# R7FA6M4AF register map
Vendor: Renesas Electronics Corporation; Series: RA6; File version: 1.30.00
CPU: CM33 r0p4, little endian, MPU, FPU, VTOR, 4 interrupt priority bits, 96 interrupts
Registers are 8-bit, read-write, reset 0x0 unless marked. A register's access mark holds for its fields unless they carry their own. Offsets are from the block's base; [hi:lo] are bit positions; {n}, {i} and the like mark numbered series; 'fields as' and 'values as' point back to an identical list.

## CAN0 — Controller Area Network 0
Base 0x400A8000
Same registers: CAN1 0x400A9000
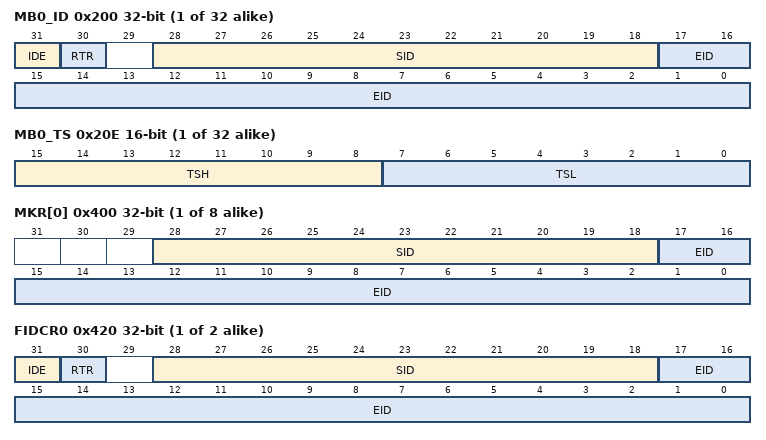
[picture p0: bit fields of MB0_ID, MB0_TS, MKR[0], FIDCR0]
{0x200+0x10*i} MB{i}_ID (i=0..31) 32-bit (reset mask 0x1) — Mailbox ID Register {i}
  [31] IDE — ID Extension
  [30] RTR — Remote Transmission Request
  [28:18] SID — Standard ID of data and remote frames
  [17:0] EID — Extended ID of data and remote frames
{0x204+0x10*i} MB{i}_DL (i=0..31) 16-bit reset not defined — Mailbox Data Length Register {i}
  [3:0] DLC — Data Length Code
{0x206+0x10*i} MB{i}_D0 (i=0..31) reset not defined — Mailbox Data Register {i}
  [7:0] DATA0 — Data Bytes 0
{0x207+0x10*i} MB{i}_D1 (i=0..31) reset not defined — Mailbox Data Register {i}
  [7:0] DATA1 — Data Bytes 1
{0x208+0x10*i} MB{i}_D2 (i=0..31) reset not defined — Mailbox Data Register {i}
  [7:0] DATA2 — Data Bytes 2
{0x209+0x10*i} MB{i}_D3 (i=0..31) reset not defined — Mailbox Data Register {i}
  [7:0] DATA3 — Data Bytes 3
{0x20A+0x10*i} MB{i}_D4 (i=0..31) reset not defined — Mailbox Data Register {i}
  [7:0] DATA4 — Data Bytes 4
{0x20B+0x10*i} MB{i}_D5 (i=0..31) reset not defined — Mailbox Data Register {i}
  [7:0] DATA5 — Data Bytes 5
{0x20C+0x10*i} MB{i}_D6 (i=0..31) reset not defined — Mailbox Data Register {i}
  [7:0] DATA6 — Data Bytes 6
{0x20D+0x10*i} MB{i}_D7 (i=0..31) reset not defined — Mailbox Data Register {i}
  [7:0] DATA7 — Data Bytes 7
{0x20E+0x10*i} MB{i}_TS (i=0..31) 16-bit reset not defined — Mailbox Time Stamp Register {i}
  [15:8] TSH — Time Stamp Higher Byte
  [7:0] TSL — Time Stamp Lower Byte
{0x400+4i} MKR[{i}] (i=0..7) 32-bit reset not defined — Mask Register {i}
  [28:18] SID — Standard ID
  [17:0] EID — Extended ID
{0x420+4i} FIDCR{i} (i=0..1) 32-bit reset not defined — FIFO Received ID Compare Register {i}
  fields as MB0_ID
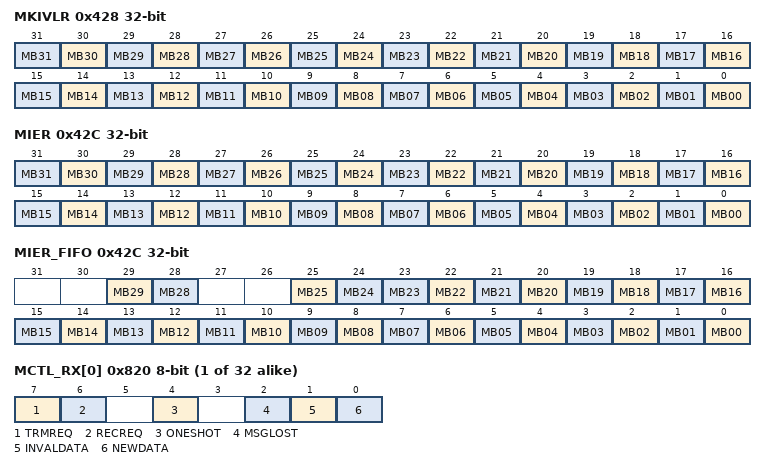
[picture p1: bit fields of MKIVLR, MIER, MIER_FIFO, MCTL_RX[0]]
0x428 MKIVLR 32-bit reset not defined — Mask Invalid Register
  [n] MB{n:02} (n=0..31) — Mask Invalid
0x42C MIER 32-bit reset not defined — Mailbox Interrupt Enable Register
  [n] MB{n:02} (n=0..31) — Interrupt Enable
0x42C MIER_FIFO 32-bit reset not defined (alternate view of MIER) — Mailbox Interrupt Enable Register for FIFO Mailbox Mode
  [29] MB29 — Receive FIFO Interrupt Generation Timing Control
  [28] MB28 — Receive FIFO Interrupt Enable
  [25] MB25 — Transmit FIFO Interrupt Generation Timing Control
  [24] MB24 — Transmit FIFO Interrupt Enable
  [n] MB{n:02} (n=0..23) — Interrupt Enable
{0x820+i} MCTL_RX[{i}] (i=0..31) — Message Control Register for Receive
  [7] TRMREQ — Transmit Mailbox Request
  [6] RECREQ — Receive Mailbox Request
  [4] ONESHOT — One,Shot Enable
  [2] MSGLOST — Message Lost Flag
  [1] INVALDATA ro — Reception,in,Progress Status Flag
  [0] NEWDATA — Reception Complete Flag
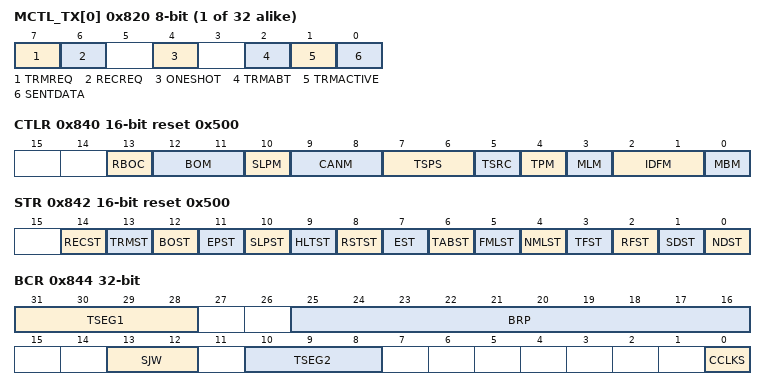
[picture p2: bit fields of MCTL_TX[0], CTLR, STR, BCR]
{0x820+i} MCTL_TX[{i}] (i=0..31) (alternate view of MCTL_RX[{i}]) — Message Control Register for Transmit
  [7] TRMREQ — Transmit Mailbox Request
  [6] RECREQ — Receive Mailbox Request
  [4] ONESHOT — One,Shot Enable
  [2] TRMABT — Transmission Abort Complete Flag
  [1] TRMACTIVE ro — Transmission,in,Progress Status Flag
  [0] SENTDATA — Transmission Complete Flag
0x840 CTLR 16-bit reset 0x500 — Control Register
  [13] RBOC — Forcible Return from Bus,Off
  [12:11] BOM — Bus,Off Recovery Mode
  [10] SLPM — CAN Sleep Mode
  [9:8] CANM — CAN Operating Mode Select
  [7:6] TSPS — Time Stamp Prescaler Select
  [5] TSRC — Time Stamp Counter Reset Command
  [4] TPM — Transmission Priority Mode Select
  [3] MLM — Message Lost Mode Select
  [2:1] IDFM — ID Format Mode Select
  [0] MBM — CAN Mailbox Mode Select
0x842 STR 16-bit ro reset 0x500 — Status Register
  [14] RECST — Receive Status Flag
  [13] TRMST — Transmit Status Flag
  [12] BOST — Bus,Off Status Flag
  [11] EPST — Error,Passive Status Flag
  [10] SLPST — CAN Sleep Status Flag
  [9] HLTST — CAN Halt Status Flag
  [8] RSTST — CAN Reset Status Flag
  [7] EST — Error Status Flag
  [6] TABST — Transmission Abort Status Flag
  [5] FMLST — FIFO Mailbox Message Lost Status Flag
  [4] NMLST — Normal Mailbox Message Lost Status Flag
  [3] TFST — Transmit FIFO Status Flag
  [2] RFST — Receive FIFO Status Flag
  [1] SDST — SENTDATA Status Flag
  [0] NDST — NEWDATA Status Flag
0x844 BCR 32-bit — Bit Configuration Register
  [31:28] TSEG1 — Time Segment 1 Control
  [25:16] BRP — Baud Rate Prescaler Select
  [13:12] SJW — Synchronization Jump Width Control
  [10:8] TSEG2 — Time Segment 2 Control
  [0] CCLKS — CAN Clock Source Selection
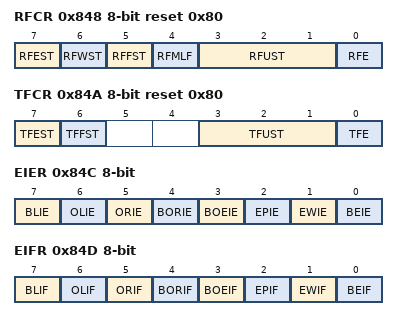
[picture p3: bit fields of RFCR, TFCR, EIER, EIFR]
0x848 RFCR reset 0x80 — Receive FIFO Control Register
  [7] RFEST ro — Receive FIFO Empty Status Flag
  [6] RFWST ro — Receive FIFO Buffer Warning Status Flag
  [5] RFFST ro — Receive FIFO Full Status Flag
  [4] RFMLF — Receive FIFO Message Lost Flag
  [3:1] RFUST ro — Receive FIFO Unread Message Number Status
  [0] RFE — Receive FIFO Enable
0x849 RFPCR wo reset not defined — Receive FIFO Pointer Control Register
0x84A TFCR reset 0x80 — Transmit FIFO Control Register
  [7] TFEST ro — Transmit FIFO Empty Status
  [6] TFFST ro — Transmit FIFO Full Status
  [3:1] TFUST ro — Transmit FIFO Unsent Message Number Status
  [0] TFE — Transmit FIFO Enable
0x84B TFPCR wo reset not defined — Transmit FIFO Pointer Control Register
0x84C EIER — Error Interrupt Enable Register
  [7] BLIE — Bus Lock Interrupt Enable
  [6] OLIE — Overload Frame Transmit Interrupt Enable
  [5] ORIE — Overrun Interrupt Enable
  [4] BORIE — Bus,Off Recovery Interrupt Enable
  [3] BOEIE — Bus,Off Entry Interrupt Enable
  [2] EPIE — Error,Passive Interrupt Enable
  [1] EWIE — Error,Warning Interrupt Enable
  [0] BEIE — Bus Error Interrupt Enable
0x84D EIFR — Error Interrupt Factor Judge Register
  [7] BLIF — Bus Lock Detect Flag
  [6] OLIF — Overload Frame Transmission Detect Flag
  [5] ORIF — Receive Overrun Detect Flag
  [4] BORIF — Bus,Off Recovery Detect Flag
  [3] BOEIF — Bus,Off Entry Detect Flag
  [2] EPIF — Error,Passive Detect Flag
  [1] EWIF — Error,Warning Detect Flag
  [0] BEIF — Bus Error Detect Flag
0x84E RECR ro — Receive Error Count Register
0x84F TECR ro — Transmit Error Count Register
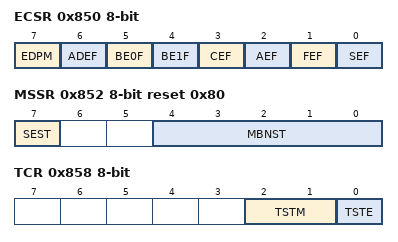
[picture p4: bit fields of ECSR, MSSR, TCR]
0x850 ECSR — Error Code Store Register
  [7] EDPM — Error Display Mode Select
  [6] ADEF — ACK Delimiter Error Flag
  [5] BE0F — Bit Error (dominant) Flag
  [4] BE1F — Bit Error (recessive) Flag
  [3] CEF — CRC Error Flag
  [2] AEF — ACK Error Flag
  [1] FEF — Form Error Flag
  [0] SEF — Stuff Error Flag
0x851 CSSR reset not defined — Channel Search Support Register
0x852 MSSR ro reset 0x80 — Mailbox Search Status Register
  [7] SEST — Search Result Status
  [4:0] MBNST — Search Result Mailbox Number Status
0x853 MSMR — Mailbox Search Mode Register
  [1:0] MBSM — Mailbox Search Mode Select
0x854 TSR 16-bit ro — Time Stamp Register
0x856 AFSR 16-bit reset not defined — Acceptance Filter Support Register
0x858 TCR — Test Control Register
  [2:1] TSTM — CAN Test Mode Select
  [0] TSTE — CAN Test Mode Enable
